# iostm32f205zx register map
Registers are 32-bit, access not given, no defined reset value unless marked. A register's access mark holds for its fields unless they carry their own. Addresses are absolute; registers are grouped by the start of their names; [hi:lo] are bit positions; {n}, {i} and the like mark numbered series; 'fields as' and 'values as' point back to an identical list.

## GPIOH
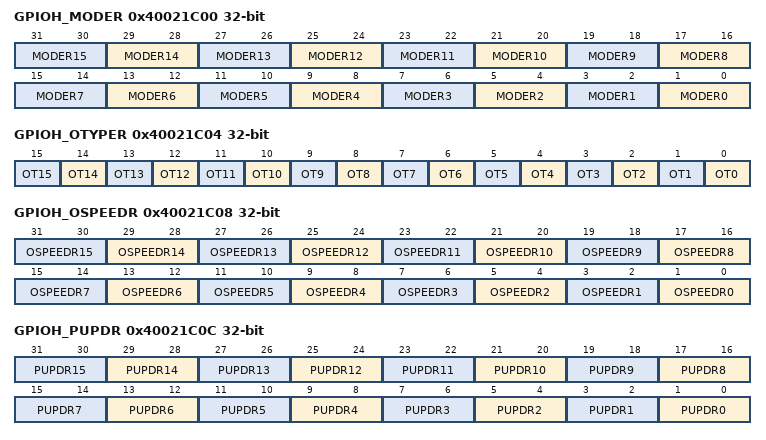
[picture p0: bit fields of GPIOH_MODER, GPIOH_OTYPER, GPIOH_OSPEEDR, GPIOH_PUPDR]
0x40021C00 GPIOH_MODER
  [2n+1:2n] MODER{n} (n=0..15)
0x40021C04 GPIOH_OTYPER
  [n] OT{n} (n=0..15)
0x40021C08 GPIOH_OSPEEDR
  [2n+1:2n] OSPEEDR{n} (n=0..15)
0x40021C0C GPIOH_PUPDR
  [2n+1:2n] PUPDR{n} (n=0..15)
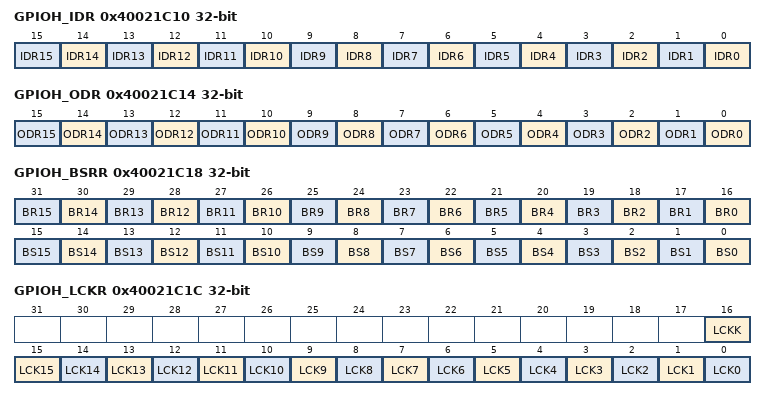
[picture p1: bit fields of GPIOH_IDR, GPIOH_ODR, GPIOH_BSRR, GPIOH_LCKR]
0x40021C10 GPIOH_IDR
  [n] IDR{n} (n=0..15)
0x40021C14 GPIOH_ODR
  [n] ODR{n} (n=0..15)
0x40021C18 GPIOH_BSRR
  [n+16] BR{n} (n=0..15), [n] BS{n} (n=0..15)
0x40021C1C GPIOH_LCKR
  [16] LCKK, [n] LCK{n} (n=0..15)
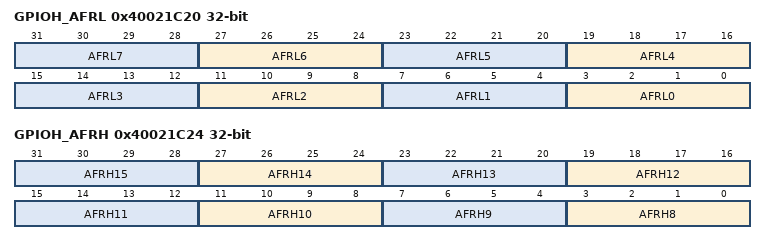
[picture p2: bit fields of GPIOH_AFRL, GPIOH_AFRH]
0x40021C20 GPIOH_AFRL
  [4n+3:4n] AFRL{n} (n=0..7)
0x40021C24 GPIOH_AFRH
  [4n-29:4n-32] AFRH{n} (n=8..15)

## GPIOI
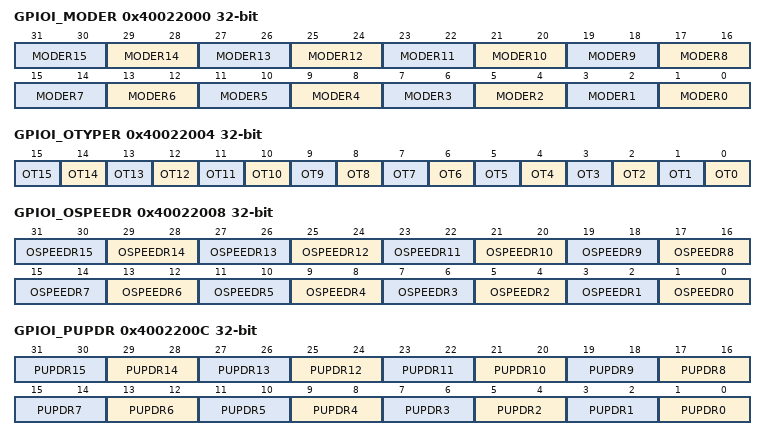
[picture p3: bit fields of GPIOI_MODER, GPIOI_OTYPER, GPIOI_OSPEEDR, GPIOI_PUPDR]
0x40022000 GPIOI_MODER
  [2n+1:2n] MODER{n} (n=0..15)
0x40022004 GPIOI_OTYPER
  [n] OT{n} (n=0..15)
0x40022008 GPIOI_OSPEEDR
  [2n+1:2n] OSPEEDR{n} (n=0..15)
0x4002200C GPIOI_PUPDR
  [2n+1:2n] PUPDR{n} (n=0..15)
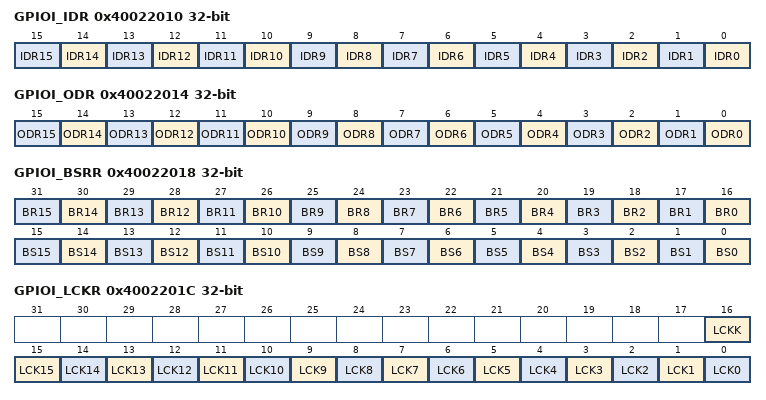
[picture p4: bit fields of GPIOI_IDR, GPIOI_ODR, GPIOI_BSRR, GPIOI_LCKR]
0x40022010 GPIOI_IDR
  [n] IDR{n} (n=0..15)
0x40022014 GPIOI_ODR
  [n] ODR{n} (n=0..15)
0x40022018 GPIOI_BSRR
  [n+16] BR{n} (n=0..15), [n] BS{n} (n=0..15)
0x4002201C GPIOI_LCKR
  [16] LCKK, [n] LCK{n} (n=0..15)
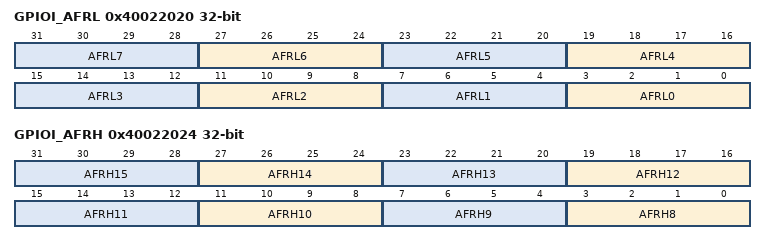
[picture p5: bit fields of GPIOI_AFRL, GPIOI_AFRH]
0x40022020 GPIOI_AFRL
  [4n+3:4n] AFRL{n} (n=0..7)
0x40022024 GPIOI_AFRH
  [4n-29:4n-32] AFRH{n} (n=8..15)

## SYSCFG
0x40013800 SYSCFG_MEMRMP
  [1:0] MEM_MODE
0x40013804 SYSCFG_PMC
  [23] MII_RMII_SEL
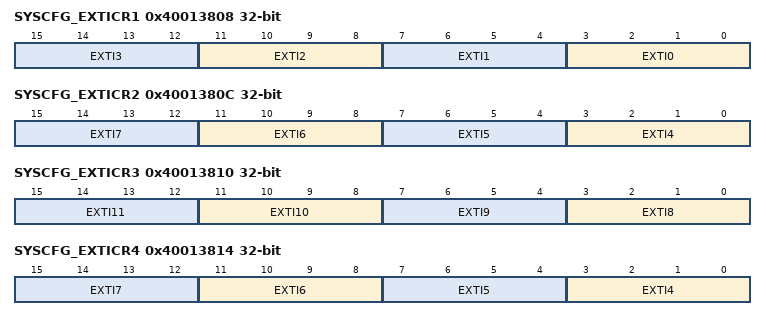
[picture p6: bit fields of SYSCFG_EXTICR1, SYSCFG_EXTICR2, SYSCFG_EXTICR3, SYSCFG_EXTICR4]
0x40013808 SYSCFG_EXTICR1
  [4n+3:4n] EXTI{n} (n=0..3)
0x4001380C SYSCFG_EXTICR2
  [4n-13:4n-16] EXTI{n} (n=4..7)
0x40013810 SYSCFG_EXTICR3
  [4n-29:4n-32] EXTI{n} (n=8..11)
0x40013814 SYSCFG_EXTICR4
  [4n-13:4n-16] EXTI{n} (n=4..7)

## EXTI
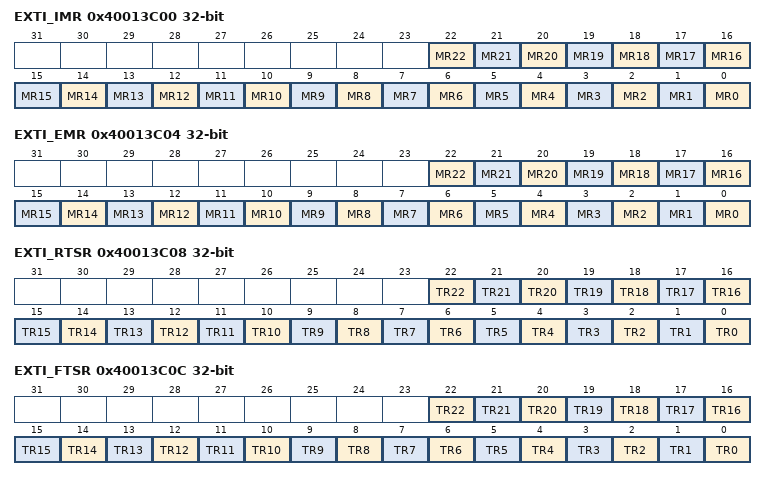
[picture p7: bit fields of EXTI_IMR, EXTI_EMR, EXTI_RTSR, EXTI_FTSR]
0x40013C00 EXTI_IMR
  [n] MR{n} (n=0..22)
0x40013C04 EXTI_EMR
  [n] MR{n} (n=0..22)
0x40013C08 EXTI_RTSR
  [n] TR{n} (n=0..22)
0x40013C0C EXTI_FTSR
  [n] TR{n} (n=0..22)
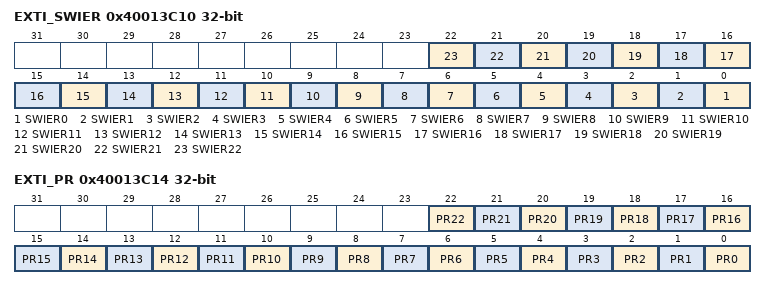
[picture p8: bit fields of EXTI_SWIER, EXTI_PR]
0x40013C10 EXTI_SWIER
  [n] SWIER{n} (n=0..22)
0x40013C14 EXTI_PR
  [n] PR{n} (n=0..22)

## DMA1
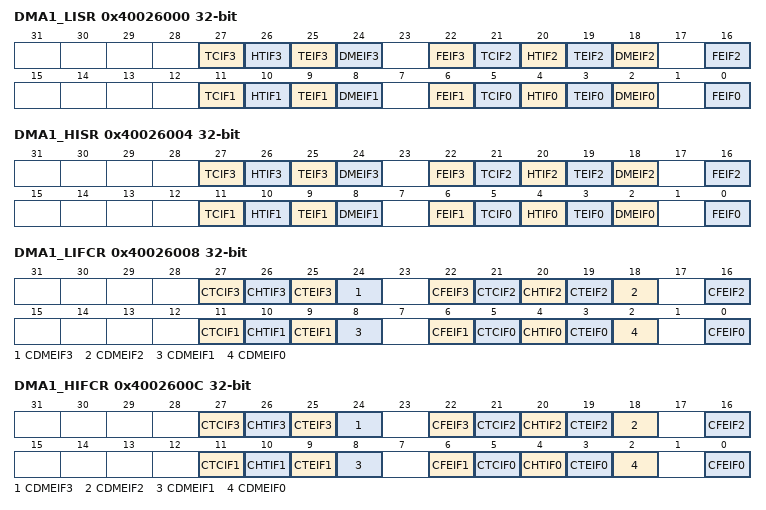
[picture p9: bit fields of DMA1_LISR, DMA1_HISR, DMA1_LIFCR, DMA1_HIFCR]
0x40026000 DMA1_LISR
  [27] TCIF3, [26] HTIF3, [25] TEIF3, [24] DMEIF3, [22] FEIF3, [21] TCIF2, [20] HTIF2, [19] TEIF2, [18] DMEIF2, [16] FEIF2, [11] TCIF1, [10] HTIF1, [9] TEIF1, [8] DMEIF1, [6] FEIF1, [5] TCIF0, [4] HTIF0, [3] TEIF0, [2] DMEIF0, [0] FEIF0
0x40026004 DMA1_HISR
  fields as DMA1_LISR
0x40026008 DMA1_LIFCR
  [27] CTCIF3, [26] CHTIF3, [25] CTEIF3, [24] CDMEIF3, [22] CFEIF3, [21] CTCIF2, [20] CHTIF2, [19] CTEIF2, [18] CDMEIF2, [16] CFEIF2, [11] CTCIF1, [10] CHTIF1, [9] CTEIF1, [8] CDMEIF1, [6] CFEIF1, [5] CTCIF0, [4] CHTIF0, [3] CTEIF0, [2] CDMEIF0, [0] CFEIF0
0x4002600C DMA1_HIFCR
  fields as DMA1_LIFCR
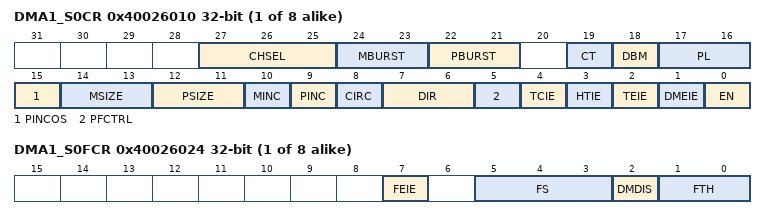
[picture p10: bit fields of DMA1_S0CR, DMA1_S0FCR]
{0x40026010+0x18*i} DMA1_S{i}CR (i=0..7)
  [27:25] CHSEL, [24:23] MBURST, [22:21] PBURST, [19] CT, [18] DBM, [17:16] PL, [15] PINCOS, [14:13] MSIZE, [12:11] PSIZE, [10] MINC, [9] PINC, [8] CIRC, [7:6] DIR, [5] PFCTRL, [4] TCIE, [3] HTIE, [2] TEIE, [1] DMEIE, [0] EN
{0x40026014+0x18*i} DMA1_S{i}NDTR (i=0..7)
  [15:0] NDT
{0x40026018+0x18*i} DMA1_S{i}PAR (i=0..7)
{0x4002601C+0x18*i} DMA1_S{i}M0AR (i=0..7)
{0x40026020+0x18*i} DMA1_S{i}M1AR (i=0..7)
{0x40026024+0x18*i} DMA1_S{i}FCR (i=0..7)
  [7] FEIE, [5:3] FS, [2] DMDIS, [1:0] FTH

## DMA2
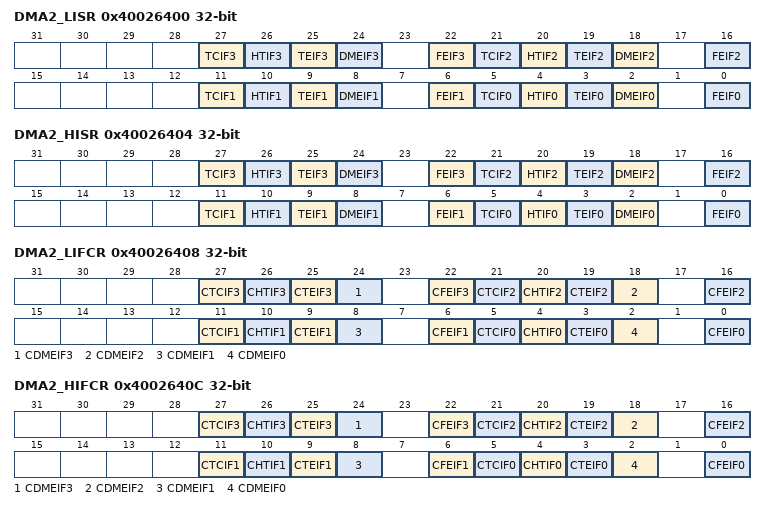
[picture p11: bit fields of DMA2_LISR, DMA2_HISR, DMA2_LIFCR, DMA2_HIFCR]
0x40026400 DMA2_LISR
  [27] TCIF3, [26] HTIF3, [25] TEIF3, [24] DMEIF3, [22] FEIF3, [21] TCIF2, [20] HTIF2, [19] TEIF2, [18] DMEIF2, [16] FEIF2, [11] TCIF1, [10] HTIF1, [9] TEIF1, [8] DMEIF1, [6] FEIF1, [5] TCIF0, [4] HTIF0, [3] TEIF0, [2] DMEIF0, [0] FEIF0
0x40026404 DMA2_HISR
  fields as DMA2_LISR
0x40026408 DMA2_LIFCR
  [27] CTCIF3, [26] CHTIF3, [25] CTEIF3, [24] CDMEIF3, [22] CFEIF3, [21] CTCIF2, [20] CHTIF2, [19] CTEIF2, [18] CDMEIF2, [16] CFEIF2, [11] CTCIF1, [10] CHTIF1, [9] CTEIF1, [8] CDMEIF1, [6] CFEIF1, [5] CTCIF0, [4] CHTIF0, [3] CTEIF0, [2] CDMEIF0, [0] CFEIF0
0x4002640C DMA2_HIFCR
  fields as DMA2_LIFCR
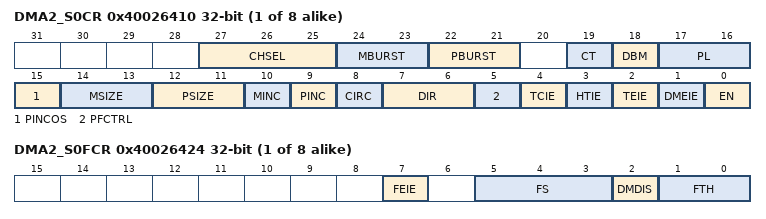
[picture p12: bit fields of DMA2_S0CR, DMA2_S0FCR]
{0x40026410+0x18*i} DMA2_S{i}CR (i=0..7)
  [27:25] CHSEL, [24:23] MBURST, [22:21] PBURST, [19] CT, [18] DBM, [17:16] PL, [15] PINCOS, [14:13] MSIZE, [12:11] PSIZE, [10] MINC, [9] PINC, [8] CIRC, [7:6] DIR, [5] PFCTRL, [4] TCIE, [3] HTIE, [2] TEIE, [1] DMEIE, [0] EN
{0x40026414+0x18*i} DMA2_S{i}NDTR (i=0..7)
  [15:0] NDT
{0x40026418+0x18*i} DMA2_S{i}PAR (i=0..7)
{0x4002641C+0x18*i} DMA2_S{i}M0AR (i=0..7)
{0x40026420+0x18*i} DMA2_S{i}M1AR (i=0..7)
{0x40026424+0x18*i} DMA2_S{i}FCR (i=0..7)
  [7] FEIE, [5:3] FS, [2] DMDIS, [1:0] FTH
